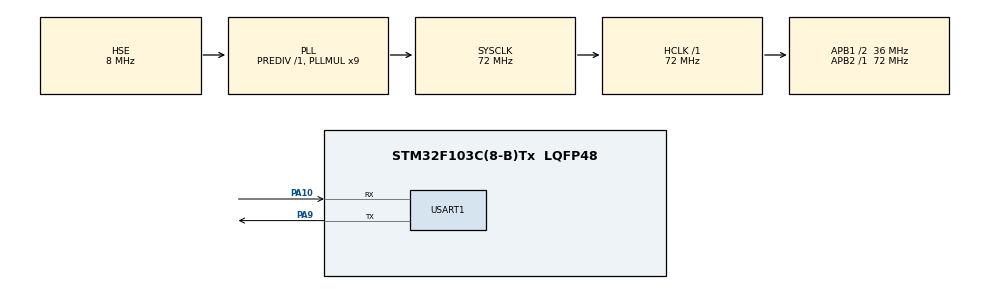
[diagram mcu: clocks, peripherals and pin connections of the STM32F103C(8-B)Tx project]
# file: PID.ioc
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Mcu.Family=STM32F1
RCC.PLLSourceVirtual=RCC_PLLSOURCE_HSE
PC15-OSC32_OUT.Mode=LSE-External-Oscillator
PD1-OSC_OUT.Mode=HSE-External-Oscillator
PA10.Mode=Asynchronous
PD0-OSC_IN.Signal=RCC_OSC_IN
RCC.APB1CLKDivider=RCC_HCLK_DIV2
PC14-OSC32_IN.Signal=RCC_OSC32_IN
RCC.SYSCLKSource=RCC_SYSCLKSOURCE_PLLCLK
ProjectManager.StackSize=0x400
PD1-OSC_OUT.Signal=RCC_OSC_OUT
PA13.Signal=SYS_JTMS-SWDIO
PA9.Mode=Asynchronous
ProjectManager.TargetToolchain=STM32CubeIDE
RCC.HCLKFreq_Value=72000000
RCC.APB2TimFreq_Value=72000000
PA9.Signal=USART1_TX
RCC.USBFreq_Value=72000000
PC15-OSC32_OUT.Signal=RCC_OSC32_OUT
RCC.AHBFreq_Value=72000000
PD0-OSC_IN.Mode=HSE-External-Oscillator
board=custom
RCC.PLLMUL=RCC_PLL_MUL9
RCC.APB2Freq_Value=72000000
PC14-OSC32_IN.Mode=LSE-External-Oscillator
PA14.Mode=Serial_Wire
PA13.Mode=Serial_Wire
Mcu.Name=STM32F103C(8-B)Tx
RCC.SYSCLKFreq_VALUE=72000000
Mcu.Package=LQFP48
USART1.VirtualMode=VM_ASYNC
PA10.Signal=USART1_RX
PA14.Signal=SYS_JTCK-SWCLK
ProjectManager.HeapSize=0x200
NVIC.PriorityGroup=NVIC_PRIORITYGROUP_4
RCC.APB1TimFreq_Value=72000000
NVIC.USART1_IRQn=true\:0\:0\:false\:false\:true\:true\:true
RCC.APB1Freq_Value=36000000
NVIC.RCC_IRQn=true\:0\:0\:false\:false\:true\:true\:false

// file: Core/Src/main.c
/* USER CODE BEGIN Header */
/**
 ******************************************************************************
 * @file           : main.c
 * @brief          : Main program body
 ******************************************************************************
 * @attention
 *
 * <h2><center>&copy; Copyright (c) 2021 STMicroelectronics.
 * All rights reserved.</center></h2>
 *
 * This software component is licensed by ST under BSD 3-Clause license,
 * the "License"; You may not use this file except in compliance with the
 * License. You may obtain a copy of the License at:
 *                        opensource.org/licenses/BSD-3-Clause
 *
 ******************************************************************************
 */
/* USER CODE END Header */
#include "main.h"
#include "usart.h"
#include "gpio.h"
#include "pid.h"

/* USER CODE BEGIN Includes */
#include "stdio.h"
#include "stdlib.h"
#include "string.h"
#include "math.h"

/* USER CODE END Includes */

/* USER CODE BEGIN PV */

uint8_t RecvBuff[5] = { 0 };

PID_HandleTypeDef pid1;
PID_HandleTypeDef pid2;
float PID_Target = 0.0;

/* USER CODE END PV */

void SystemClock_Config(void);

int main(void) {

	/* MCU Configuration--------------------------------------------------------*/

	/* Reset of all peripherals, Initializes the Flash interface and the Systick. */
	HAL_Init();

	/* Configure the system clock */
	SystemClock_Config();

	/* USER CODE BEGIN SysInit */

	PID_Init(&pid1, 0.736, 0.135, 0.064);
	PID_Init(&pid2, 0.4, 0.2, 0.2);
	/* USER CODE END SysInit */

	/* Initialize all configured peripherals */
	MX_GPIO_Init();
	MX_USART1_UART_Init();
	/* USER CODE BEGIN 2 */
	HAL_UART_Receive_IT(&huart1, RecvBuff, sizeof(RecvBuff));

	printf("System start up!\n");

	/* USER CODE END 2 */

	/* Infinite loop */
	while (1) {

	}
}

void SystemClock_Config(void) {
	RCC_OscInitTypeDef RCC_OscInitStruct = { 0 };
	RCC_ClkInitTypeDef RCC_ClkInitStruct = { 0 };

	/** Initializes the RCC Oscillators according to the specified parameters
	 * in the RCC_OscInitTypeDef structure.
	 */
	RCC_OscInitStruct.OscillatorType = RCC_OSCILLATORTYPE_HSE;
	RCC_OscInitStruct.HSEState = RCC_HSE_ON;
	RCC_OscInitStruct.HSEPredivValue = RCC_HSE_PREDIV_DIV1;
	RCC_OscInitStruct.HSIState = RCC_HSI_ON;
	RCC_OscInitStruct.PLL.PLLState = RCC_PLL_ON;
	RCC_OscInitStruct.PLL.PLLSource = RCC_PLLSOURCE_HSE;
	RCC_OscInitStruct.PLL.PLLMUL = RCC_PLL_MUL9;
	if (HAL_RCC_OscConfig(&RCC_OscInitStruct) != HAL_OK) {
		Error_Handler();
	}
	/** Initializes the CPU, AHB and APB buses clocks
	 */
	RCC_ClkInitStruct.ClockType = RCC_CLOCKTYPE_HCLK | RCC_CLOCKTYPE_SYSCLK
			| RCC_CLOCKTYPE_PCLK1 | RCC_CLOCKTYPE_PCLK2;
	RCC_ClkInitStruct.SYSCLKSource = RCC_SYSCLKSOURCE_PLLCLK;
	RCC_ClkInitStruct.AHBCLKDivider = RCC_SYSCLK_DIV1;
	RCC_ClkInitStruct.APB1CLKDivider = RCC_HCLK_DIV2;
	RCC_ClkInitStruct.APB2CLKDivider = RCC_HCLK_DIV1;

	if (HAL_RCC_ClockConfig(&RCC_ClkInitStruct, FLASH_LATENCY_2) != HAL_OK) {
		Error_Handler();
	}
}

/* USER CODE BEGIN 4 */

void HAL_UART_RxCpltCallback(UART_HandleTypeDef *huart) {
	if (huart->Instance == USART1) {

		PID_Target = (float) atoff((const char*) RecvBuff);

		printf("Beginning value: %f\n", pid1.ActualValue);
		int i = 0;
		float output = 0.0;
		while (i < 200) {
			i++;
			output = PID_Model_Positional(&pid1, PID_Target);
			printf("%f\n", output);
			if (pid1.Accuracy > PID_GetOffsetModul(PID_Target - output))
				break;

		}
		printf("PID Finished!\n");

		//printf("%f\n",PID_Model_Incremental(&pid1, PID_Target));
		//printf("PID Finished!\n");

		HAL_UART_Receive_IT(&huart1, RecvBuff, sizeof(RecvBuff));
	}
}

/* USER CODE END 4 */

void Error_Handler(void) {
	__disable_irq();
	while (1) {
	}
}

/************************ (C) COPYRIGHT STMicroelectronics *****END OF FILE****/
